VERSION ""

NS_ :

BS_:

BU_:

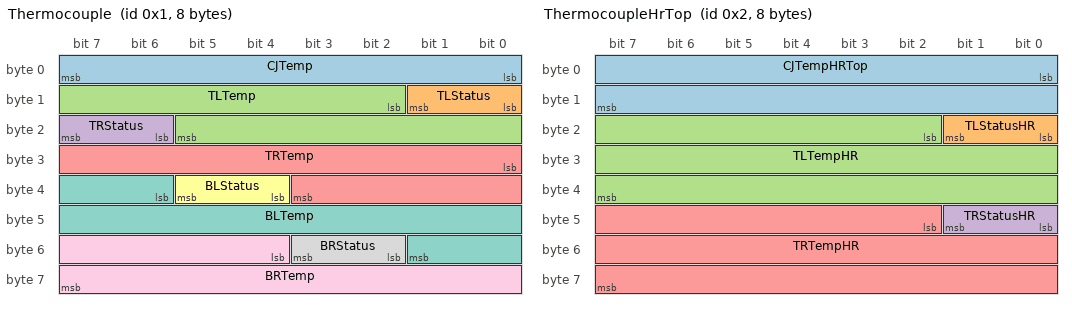
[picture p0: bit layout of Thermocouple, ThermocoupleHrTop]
BO_ 1 Thermocouple: 8 Vector__XXX
 SG_ CJTemp : 0|8@1+ (1,-128) [-20|85] "degC" Vector__XXX
 SG_ TLStatus : 8|2@1+ (1,0) [0|3] "" Vector__XXX
 SG_ TLTemp : 10|12@1+ (1,-2048) [-210|1800] "degC" Vector__XXX
 SG_ TRStatus : 22|2@1+ (1,0) [0|3] "" Vector__XXX
 SG_ TRTemp : 24|12@1+ (1,-2048) [-210|1800] "degC" Vector__XXX
 SG_ BLStatus : 36|2@1+ (1,0) [0|3] "" Vector__XXX
 SG_ BLTemp : 38|12@1+ (1,-2048) [-210|1800] "degC" Vector__XXX
 SG_ BRStatus : 50|2@1+ (1,0) [0|3] "" Vector__XXX
 SG_ BRTemp : 52|12@1+ (1,-2048) [-210|1800] "degC" Vector__XXX

BO_ 2 ThermocoupleHrTop: 8 Vector__XXX
 SG_ CJTempHRTop : 0|16@1+ (0.015625,-512) [-20|85] "degC" Vector__XXX
 SG_ TLStatusHR : 16|2@1+ (1,0) [0|3] "" Vector__XXX
 SG_ TLTempHR : 18|22@1+ (0.0078125,-16384) [-210|1800] "degC" Vector__XXX
 SG_ TRStatusHR : 40|2@1+ (1,0) [0|3] "" Vector__XXX
 SG_ TRTempHR : 42|22@1+ (0.0078125,-16384) [-210|1800] "degC" Vector__XXX

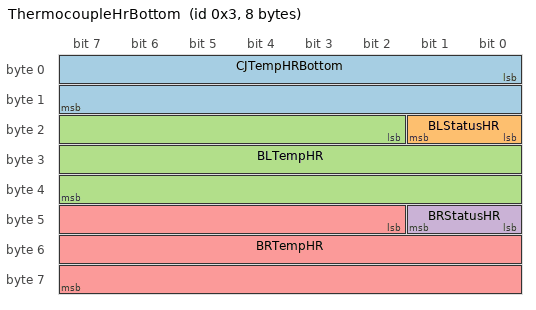
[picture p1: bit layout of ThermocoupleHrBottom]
BO_ 3 ThermocoupleHrBottom: 8 Vector__XXX
 SG_ CJTempHRBottom : 0|16@1+ (0.015625,-512) [-20|85] "degC" Vector__XXX
 SG_ BLStatusHR : 16|2@1+ (1,0) [0|3] "" Vector__XXX
 SG_ BLTempHR : 18|22@1+ (0.0078125,-16384) [-210|1800] "degC" Vector__XXX
 SG_ BRStatusHR : 40|2@1+ (1,0) [0|3] "" Vector__XXX
 SG_ BRTempHR : 42|22@1+ (0.0078125,-16384) [-210|1800] "degC" Vector__XXX

CM_ BO_ 1 "Standard resolution, all";
CM_ SG_ 1 CJTemp "Cold junction temperature";
CM_ SG_ 1 TLStatus "Top-Left status";
CM_ SG_ 1 TLTemp "Top-Left temperature";
CM_ SG_ 1 TRStatus "Top-Right status";
CM_ SG_ 1 TRTemp "Top-Right temperature";
CM_ SG_ 1 BLStatus "Bottom-Left status";
CM_ SG_ 1 BLTemp "Bottom-Left temperature";
CM_ SG_ 1 BRStatus "Bottom-Right status";
CM_ SG_ 1 BRTemp "Bottom-Right temperature";
CM_ BO_ 2 "High resolution, top";
CM_ SG_ 2 CJTempHRTop "Cold junction temperature";
CM_ SG_ 2 TLStatusHR "Top-Left status";
CM_ SG_ 2 TLTempHR "Top-Left temperature";
CM_ SG_ 2 TRStatusHR "Top-Right status";
CM_ SG_ 2 TRTempHR "Top-Right temperature";
CM_ BO_ 3 "High resolution, bottom";
CM_ SG_ 3 CJTempHRBottom "Cold junction temperature";
CM_ SG_ 3 BLStatusHR "Bottom-Left status";
CM_ SG_ 3 BLTempHR "Bottom-Left temperature";
CM_ SG_ 3 BRStatusHR "Bottom-Right status";
CM_ SG_ 3 BRTempHR "Bottom-Right temperature";
BA_DEF_  "BusType" STRING ;
BA_DEF_  "ProtocolType" STRING ;
BA_DEF_DEF_  "BusType" "";
BA_DEF_DEF_  "ProtocolType" "";
BA_ "BusType" "CAN";
VAL_ 1 TLStatus 0 "OK" 1 "Err1" 2 "Err2" 3 "Err3" ;
VAL_ 1 TRStatus 0 "OK" 1 "Err1" 2 "Err2" 3 "Err3" ;
VAL_ 1 BLStatus 0 "OK" 1 "Err1" 2 "Err2" 3 "Err3" ;
VAL_ 1 BRStatus 0 "OK" 1 "Err1" 2 "Err2" 3 "Err3" ;
VAL_ 2 TLStatusHR 0 "OK" 1 "Err1" 2 "Err2" 3 "Err3" ;
VAL_ 2 TRStatusHR 0 "OK" 1 "Err1" 2 "Err2" 3 "Err3" ;
VAL_ 3 BLStatusHR 0 "OK" 1 "Err1" 2 "Err2" 3 "Err3" ;
VAL_ 3 BRStatusHR 0 "OK" 1 "Err1" 2 "Err2" 3 "Err3" ;
